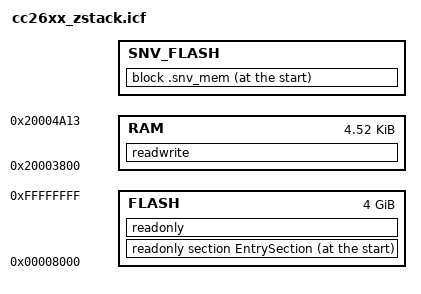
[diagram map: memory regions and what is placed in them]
/*******************************************************************************
  Filename:       cc26xx_zstack.icf
  Revised:        $Date: 2014-10-22 14:57:17 -0700 (Wed, 22 Oct 2014) $
  Revision:       $Revision: 40742 $

  Description:    IAR ARM Linker Configuration File - ZStack

  Note: Code stack and heap are allocated by the Application/RTOS build.

  Imported Symbols
  Note: Linker defines are located in the IAR IDE project using --config_def
        in Options->Linker->Extra Options, or placed in Options->Linker->
        Config->Configuration file symbol definitions.

  CCxxxx:            Device Name (e.g. CC2650)
  FLASH_ROM_BUILD:   Build Flash portion of ZStack stack to work with ROM code.
  ICALL_STACK0_ADDR: Start address of flash only and flash ROM builds.
  ICALL_RAM0_ADDR:   Start address of RAM.

  Exported Symbols
  Note: Can be used as externs in C code.

  PAGE_SIZE:         Size of Flash sector, in bytes.
  NUM_SNV_PAGES:     Number of sectors used for System NV.
  BEG_SNV_PAGE:      First Flash sector for System NV.

  Copyright 2014 Texas Instruments Incorporated. All rights reserved.

  IMPORTANT: Your use of this Software is limited to those specific rights
  granted under the terms of a software license agreement between the user
  who downloaded the software, his/her employer (which must be your employer)
  and Texas Instruments Incorporated (the "License"). You may not use this
  Software unless you agree to abide by the terms of the License. The License
  limits your use, and you acknowledge, that the Software may not be modified,
  copied or distributed unless embedded on a Texas Instruments microcontroller
  or used solely and exclusively in conjunction with a Texas Instruments radio
  frequency transceiver, which is integrated into your product. Other than for
  the foregoing purpose, you may not use, reproduce, copy, prepare derivative
  works of, modify, distribute, perform, display or sell this Software and/or
  its documentation for any purpose.

  YOU FURTHER ACKNOWLEDGE AND AGREE THAT THE SOFTWARE AND DOCUMENTATION ARE
  PROVIDED “AS IS” WITHOUT WARRANTY OF ANY KIND, EITHER EXPRESS OR IMPLIED,
  INCLUDING WITHOUT LIMITATION, ANY WARRANTY OF MERCHANTABILITY, TITLE,
  NON-INFRINGEMENT AND FITNESS FOR A PARTICULAR PURPOSE. IN NO EVENT SHALL
  TEXAS INSTRUMENTS OR ITS LICENSORS BE LIABLE OR OBLIGATED UNDER CONTRACT,
  NEGLIGENCE, STRICT LIABILITY, CONTRIBUTION, BREACH OF WARRANTY, OR OTHER
  LEGAL EQUITABLE THEORY ANY DIRECT OR INDIRECT DAMAGES OR EXPENSES
  INCLUDING BUT NOT LIMITED TO ANY INCIDENTAL, SPECIAL, INDIRECT, PUNITIVE
  OR CONSEQUENTIAL DAMAGES, LOST PROFITS OR LOST DATA, COST OF PROCUREMENT
  OF SUBSTITUTE GOODS, TECHNOLOGY, SERVICES, OR ANY CLAIMS BY THIRD PARTIES
  (INCLUDING BUT NOT LIMITED TO ANY DEFENSE THEREOF), OR OTHER SIMILAR COSTS.

  Should you have any questions regarding your right to use this Software,
  contact Texas Instruments Incorporated at www.TI.com.
*******************************************************************************/

////////////////////////////////////////////////////////////////////////////////
// Memory Sizes
////////////////////////////////////////////////////////////////////////////////

if ( isdefinedsymbol(CC2630) ||
     isdefinedsymbol(CC2650) )
{
  define symbol RAM_SIZE            = 0x00005000;  // 20K
  define symbol FLASH_SIZE          = 0x00020000;  // 128K
}
////////////////////////////////////////////////////////////////////////////////
// Default
else
{
  define symbol RAM_SIZE            = 0x00004000;  // 16K
  define symbol FLASH_SIZE          = 0x00020000;  // 128K
}

////////////////////////////////////////////////////////////////////////////////
// Memory Definitions
////////////////////////////////////////////////////////////////////////////////

////////////////////////////////////////////////////////////////////////////////
// RAM
//
if ( isdefinedsymbol(FLASH_ROM_BUILD) )
{
  if ( isdefinedsymbol(ICALL_RAM0_ADDR) )
  {
    define symbol RAM_START         = ICALL_RAM0_ADDR;
  }
  else
  {
    define symbol RAM_START         = 0x20003800;
  }
  define symbol RAM_END             = 0x20004A13;
}
else // unknown build
{
  define symbol RAM_START           = 0xFFFFFFFF;
  define symbol RAM_END             = 0xFFFFFFFF;
}

////////////////////////////////////////////////////////////////////////////////
// Flash
//
define symbol PAGE_SIZE             = 0x1000;
export symbol PAGE_SIZE;

define symbol NUM_RESERVED_PAGES    = 1;
define symbol RESERVED_SIZE         = (NUM_RESERVED_PAGES * PAGE_SIZE);
define symbol RESERVED_END          = (FLASH_SIZE - 1);
define symbol RESERVED_START        = (RESERVED_END - RESERVED_SIZE + 1);

if ( !(isdefinedsymbol(NUM_SNV_PAGES)) )
{
  define symbol NUM_SNV_PAGES       = 2;
}
export symbol NUM_SNV_PAGES;

define symbol SNV_SIZE              = (NUM_SNV_PAGES * PAGE_SIZE);
define symbol SNV_END               = (RESERVED_START - 1);
define symbol SNV_START             = (SNV_END - SNV_SIZE + 1);

if ( !(isdefinedsymbol(SNV_FIRST_PAGE)) )
{
  define symbol SNV_FIRST_PAGE      = (SNV_START / PAGE_SIZE);
}
export symbol SNV_FIRST_PAGE;

if ( isdefinedsymbol(FLASH_ROM_BUILD) )
{
  if ( isdefinedsymbol(ICALL_STACK0_ADDR) )
  {
    define symbol FLASH_START       = ICALL_STACK0_ADDR;
  }
  else // default
  {
    define symbol FLASH_START       = 0x00008000;
  }
  define symbol FLASH_END           = (SNV_START-1);
}
else // unknown build
{
  define symbol FLASH_START         = 0xFFFFFFFF;
  define symbol FLASH_END           = 0xFFFFFFFF;
}

////////////////////////////////////////////////////////////////////////////////
// Memory Regions
////////////////////////////////////////////////////////////////////////////////

define memory mem with size = 4G;

define region FLASH     = mem:[from FLASH_START to FLASH_END];
define region RAM       = mem:[from RAM_START   to RAM_END];
define region SNV_FLASH = mem:[from SNV_START   to SNV_END];

////////////////////////////////////////////////////////////////////////////////
// Flash Software Entry Point
////////////////////////////////////////////////////////////////////////////////

if ( isdefinedsymbol(FLASH_ROM_BUILD) )
{
  place at start of FLASH { readonly section EntrySection };
}

////////////////////////////////////////////////////////////////////////////////
// Memory Placement
////////////////////////////////////////////////////////////////////////////////

if ( isdefinedsymbol(FLASH_ROM_BUILD) )
{
  place in FLASH { readonly };
  place in RAM { readwrite };

  // NV
  define block .snv_mem with size=SNV_SIZE, alignment=4 { ro section .snv_mem };
  place at start of SNV_FLASH { block .snv_mem };
  keep { ro section .snv_mem };
}

////////////////////////////////////////////////////////////////////////////////
// Initialization
////////////////////////////////////////////////////////////////////////////////

initialize by copy { readwrite };

do not initialize
{
  section .noinit,
  section .stack,
};

////////////////////////////////////////////////////////////////////////////////
